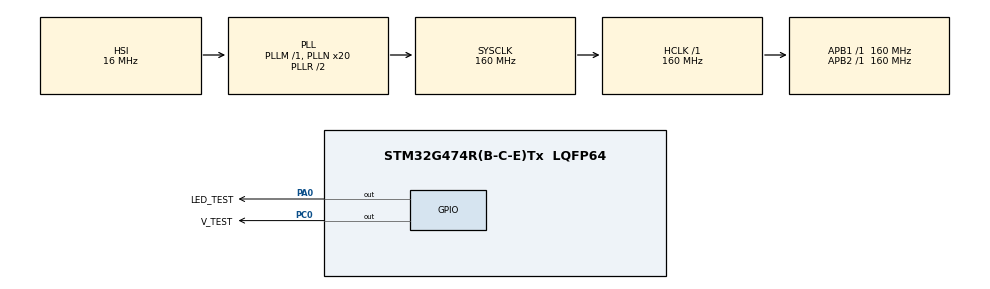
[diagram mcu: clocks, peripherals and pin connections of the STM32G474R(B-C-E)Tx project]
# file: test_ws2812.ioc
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Mcu.Family=STM32G4
Mcu.Name=STM32G474R(B-C-E)Tx
Mcu.Package=LQFP64
NVIC.PriorityGroup=NVIC_PRIORITYGROUP_4
PA0.GPIO_Label=LED_TEST
PA0.Signal=GPIO_Output
PC0.GPIO_Label=V_TEST
PC0.Signal=GPIO_Output
ProjectManager.HeapSize=0x200
ProjectManager.StackSize=0x400
ProjectManager.TargetToolchain=STM32CubeIDE
RCC.ADC12Freq_Value=160000000
RCC.ADC345Freq_Value=160000000
RCC.AHBFreq_Value=160000000
RCC.APB1Freq_Value=160000000
RCC.APB1TimFreq_Value=160000000
RCC.APB2Freq_Value=160000000
RCC.APB2TimFreq_Value=160000000
RCC.CortexFreq_Value=160000000
RCC.EXTERNAL_CLOCK_VALUE=12288000
RCC.HCLKFreq_Value=160000000
RCC.HSE_VALUE=8000000
RCC.HSI48_VALUE=48000000
RCC.HSI_VALUE=16000000
RCC.LSE_VALUE=32768
RCC.PLLN=20
RCC.SYSCLKFreq_VALUE=160000000
RCC.SYSCLKSource=RCC_SYSCLKSOURCE_PLLCLK
RCC.USBFreq_Value=160000000
RCC.VCOOutputFreq_Value=320000000
TIM1.PeriodNoDither=100
TIM1.Prescaler=12-1
VP_SYS_VS_DBSignals.Mode=DisableDeadBatterySignals
VP_TIM1_VS_ClockSourceINT.Mode=Internal
board=custom

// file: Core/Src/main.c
/* USER CODE BEGIN Header */
/**
  ******************************************************************************
  * @file           : main.c
  * @brief          : Main program body
  ******************************************************************************
  * @attention
  *
  * Copyright (c) 2024 STMicroelectronics.
  * All rights reserved.
  *
  * This software is licensed under terms that can be found in the LICENSE file
  * in the root directory of this software component.
  * If no LICENSE file comes with this software, it is provided AS-IS.
  *
  ******************************************************************************
  */
/* USER CODE END Header */
#include "main.h"

TIM_HandleTypeDef htim1;

void SystemClock_Config(void);
static void MX_GPIO_Init(void);
static void MX_TIM1_Init(void);

/* USER CODE BEGIN 0 */
// 延时函数，延时 0.0625 us
void delay_us_systick(uint32_t i) {
    uint32_t temp;
    // 设置重装载数值，例如，72 MHz 时钟下
    // 每个计数周期为 1/72 MHz = 13.8889 ns
    // 因此，9 个周期约为 125 ns，乘以 i 则为 1 微秒 * i
    SysTick->LOAD = 3*i-1;  // 注意：SysTick->LOAD 的值是计数器值 - 1
    SysTick->VAL = 0;            // 清零当前计数值
    SysTick->CTRL = SysTick_CTRL_CLKSOURCE_Msk | SysTick_CTRL_ENABLE_Msk;  // 使能 SysTick
    // 等待计数器倒计时到零
    do {
        temp = SysTick->CTRL;  // 读取当前倒计数值
    } while ((temp & SysTick_CTRL_ENABLE_Msk) && !(temp & SysTick_CTRL_COUNTFLAG_Msk));

    // 关闭 SysTick
    SysTick->CTRL = 0;
    SysTick->VAL = 0;  // 清空计数器
}

void delay_us(uint16_t us)
{
	uint16_t offset=15;
    uint16_t delay=0xffff-us-offset;				//65535-5-us，计数初值，由这个数
    										//计数到65535刚好计数us次，也就实
    										//现了nus延时
    HAL_TIM_Base_Start(&htim1);  			//开启定时器
    __HAL_TIM_SetCounter(&htim1,delay);		//设置计数值
    while(delay<0xffff-offset)
    {
        delay=__HAL_TIM_GetCounter(&htim1); //获取当前计数值
    }
    HAL_TIM_Base_Stop(&htim1);
}

void delay_nop(uint16_t n){
	for(int i=0;i<n;i++){
		__NOP();
	}
}

void send1(){
	HAL_GPIO_WritePin(V_TEST_GPIO_Port, V_TEST_Pin, GPIO_PIN_SET);
	delay_nop(8);//1us
	HAL_GPIO_WritePin(V_TEST_GPIO_Port, V_TEST_Pin, GPIO_PIN_RESET);
	__NOP();//300ns
}

void send0(){
	HAL_GPIO_WritePin(V_TEST_GPIO_Port, V_TEST_Pin, GPIO_PIN_SET);
	__NOP();
	HAL_GPIO_WritePin(V_TEST_GPIO_Port, V_TEST_Pin, GPIO_PIN_RESET);
	delay_nop(8);
}

void reset(){
	HAL_GPIO_WritePin(V_TEST_GPIO_Port, V_TEST_Pin, GPIO_PIN_RESET);
	delay_nop(500);
}

void send_byte(uint8_t code)
{
  for(uint8_t i = 8; i > 0; i--)
  {
    if(code & 0x80) // 检查最高位
    {
      send1(); // 发送 '1'
    }
    else
    {
      send0(); // 发送 '0'
    }
    code <<= 1; // 左移一位
  }
}

void sendGRB(uint8_t G, uint8_t R, uint8_t B)
{
  send_byte(G);
  send_byte(R);
  send_byte(B);
}

/* USER CODE END 0 */

int main(void)
{

  /* MCU Configuration--------------------------------------------------------*/

  /* Reset of all peripherals, Initializes the Flash interface and the Systick. */
  HAL_Init();

  /* Configure the system clock */
  SystemClock_Config();

  /* Initialize all configured peripherals */
  MX_GPIO_Init();
  MX_TIM1_Init();
  /* USER CODE BEGIN 2 */
  uint8_t j=0;
  reset();
  /* USER CODE END 2 */
  for(uint8_t i = 0;i < 3; i++)
  {
	  sendGRB(0,255,255);
	  reset();
  }
  HAL_Delay(50);
  for(uint8_t i = 0;i < 3; i++)
  {
	  sendGRB(0,0,0);
	  reset();
  }
  sendGRB(0,255,255);
  /* Infinite loop */
  while (1)
  {

    /* USER CODE BEGIN 3 */
	for(uint8_t i = 0;i < j - 1; i++)
	{
	  sendGRB(0,0,0);
	}
	sendGRB(0,255,255);
	reset();
	j++;
	if(j == 66)j = 1;
	HAL_Delay(50);
  }
  /* USER CODE END 3 */
}

void SystemClock_Config(void)
{
  RCC_OscInitTypeDef RCC_OscInitStruct = {0};
  RCC_ClkInitTypeDef RCC_ClkInitStruct = {0};

  /** Configure the main internal regulator output voltage
  */
  HAL_PWREx_ControlVoltageScaling(PWR_REGULATOR_VOLTAGE_SCALE1_BOOST);

  /** Initializes the RCC Oscillators according to the specified parameters
  * in the RCC_OscInitTypeDef structure.
  */
  RCC_OscInitStruct.OscillatorType = RCC_OSCILLATORTYPE_HSI;
  RCC_OscInitStruct.HSIState = RCC_HSI_ON;
  RCC_OscInitStruct.HSICalibrationValue = RCC_HSICALIBRATION_DEFAULT;
  RCC_OscInitStruct.PLL.PLLState = RCC_PLL_ON;
  RCC_OscInitStruct.PLL.PLLSource = RCC_PLLSOURCE_HSI;
  RCC_OscInitStruct.PLL.PLLM = RCC_PLLM_DIV1;
  RCC_OscInitStruct.PLL.PLLN = 20;
  RCC_OscInitStruct.PLL.PLLP = RCC_PLLP_DIV2;
  RCC_OscInitStruct.PLL.PLLQ = RCC_PLLQ_DIV2;
  RCC_OscInitStruct.PLL.PLLR = RCC_PLLR_DIV2;
  if (HAL_RCC_OscConfig(&RCC_OscInitStruct) != HAL_OK)
  {
    Error_Handler();
  }

  /** Initializes the CPU, AHB and APB buses clocks
  */
  RCC_ClkInitStruct.ClockType = RCC_CLOCKTYPE_HCLK|RCC_CLOCKTYPE_SYSCLK
                              |RCC_CLOCKTYPE_PCLK1|RCC_CLOCKTYPE_PCLK2;
  RCC_ClkInitStruct.SYSCLKSource = RCC_SYSCLKSOURCE_PLLCLK;
  RCC_ClkInitStruct.AHBCLKDivider = RCC_SYSCLK_DIV1;
  RCC_ClkInitStruct.APB1CLKDivider = RCC_HCLK_DIV1;
  RCC_ClkInitStruct.APB2CLKDivider = RCC_HCLK_DIV1;

  if (HAL_RCC_ClockConfig(&RCC_ClkInitStruct, FLASH_LATENCY_4) != HAL_OK)
  {
    Error_Handler();
  }
}

static void MX_TIM1_Init(void)
{

  TIM_ClockConfigTypeDef sClockSourceConfig = {0};
  TIM_MasterConfigTypeDef sMasterConfig = {0};

  htim1.Instance = TIM1;
  htim1.Init.Prescaler = 4-1;
  htim1.Init.CounterMode = TIM_COUNTERMODE_UP;
  htim1.Init.Period = 100;
  htim1.Init.ClockDivision = TIM_CLOCKDIVISION_DIV1;
  htim1.Init.RepetitionCounter = 0;
  htim1.Init.AutoReloadPreload = TIM_AUTORELOAD_PRELOAD_DISABLE;
  if (HAL_TIM_Base_Init(&htim1) != HAL_OK)
  {
    Error_Handler();
  }
  sClockSourceConfig.ClockSource = TIM_CLOCKSOURCE_INTERNAL;
  if (HAL_TIM_ConfigClockSource(&htim1, &sClockSourceConfig) != HAL_OK)
  {
    Error_Handler();
  }
  sMasterConfig.MasterOutputTrigger = TIM_TRGO_RESET;
  sMasterConfig.MasterOutputTrigger2 = TIM_TRGO2_RESET;
  sMasterConfig.MasterSlaveMode = TIM_MASTERSLAVEMODE_DISABLE;
  if (HAL_TIMEx_MasterConfigSynchronization(&htim1, &sMasterConfig) != HAL_OK)
  {
    Error_Handler();
  }

}

static void MX_GPIO_Init(void)
{
  GPIO_InitTypeDef GPIO_InitStruct = {0};

  /* GPIO Ports Clock Enable */
  __HAL_RCC_GPIOC_CLK_ENABLE();
  __HAL_RCC_GPIOA_CLK_ENABLE();

  /*Configure GPIO pin Output Level */
  HAL_GPIO_WritePin(V_TEST_GPIO_Port, V_TEST_Pin, GPIO_PIN_RESET);

  /*Configure GPIO pin Output Level */
  HAL_GPIO_WritePin(LED_TEST_GPIO_Port, LED_TEST_Pin, GPIO_PIN_RESET);

  /*Configure GPIO pin : V_TEST_Pin */
  GPIO_InitStruct.Pin = V_TEST_Pin;
  GPIO_InitStruct.Mode = GPIO_MODE_OUTPUT_PP;
  GPIO_InitStruct.Pull = GPIO_NOPULL;
  GPIO_InitStruct.Speed = GPIO_SPEED_FREQ_LOW;
  HAL_GPIO_Init(V_TEST_GPIO_Port, &GPIO_InitStruct);

  /*Configure GPIO pin : LED_TEST_Pin */
  GPIO_InitStruct.Pin = LED_TEST_Pin;
  GPIO_InitStruct.Mode = GPIO_MODE_OUTPUT_PP;
  GPIO_InitStruct.Pull = GPIO_NOPULL;
  GPIO_InitStruct.Speed = GPIO_SPEED_FREQ_LOW;
  HAL_GPIO_Init(LED_TEST_GPIO_Port, &GPIO_InitStruct);

}

void Error_Handler(void)
{
  __disable_irq();
  while (1)
  {
  }
}
